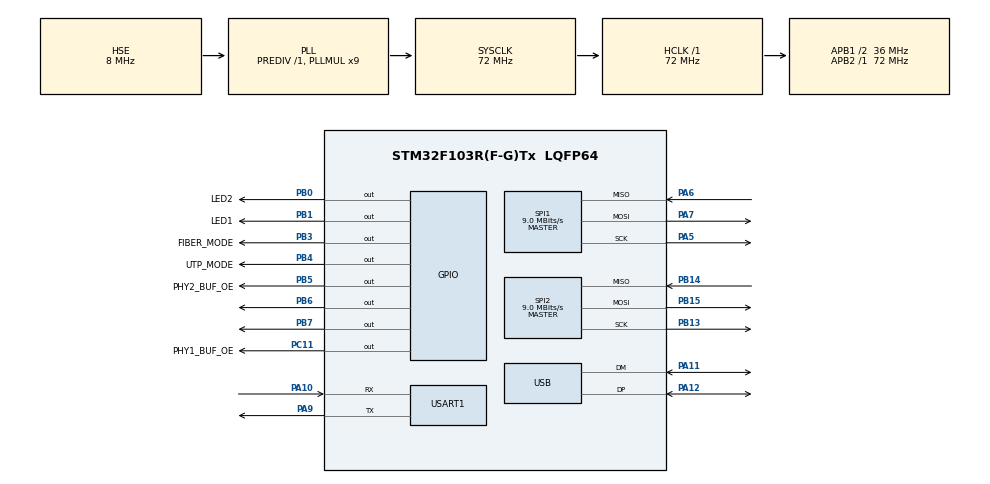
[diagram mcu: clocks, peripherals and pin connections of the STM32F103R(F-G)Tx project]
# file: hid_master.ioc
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Mcu.Family=STM32F1
PA6.Mode=Full_Duplex_Master
USB_DEVICE.CLASS_NAME_FS=CUSTOM_HID
NVIC.DMA1_Channel5_IRQn=true\:0\:0\:false\:false\:true\:false\:true
SPI1.VirtualType=VM_MASTER
Dma.USART1_TX.1.MemInc=DMA_MINC_ENABLE
SPI2.VirtualType=VM_MASTER
VP_USB_DEVICE_VS_USB_DEVICE_CUSTOM_HID_FS.Mode=CUSTOM_HID_FS
PA11.Mode=Device
PB0.GPIO_Label=LED2
PB13.Signal=SPI2_SCK
PB15.Signal=SPI2_MOSI
RCC.SYSCLKSource=RCC_SYSCLKSOURCE_PLLCLK
ProjectManager.StackSize=0x1200
PD1-OSC_OUT.Signal=RCC_OSC_OUT
PA12.Signal=USB_DP
USB_DEVICE.PID_CUSTOMHID_FS=0x00de
PB0.PinState=GPIO_PIN_SET
PB3.PinState=GPIO_PIN_SET
SPI1.Direction=SPI_DIRECTION_2LINES
RCC.HCLKFreq_Value=72000000
RCC.APB2TimFreq_Value=72000000
PB6.Signal=GPIO_Output
SPI1.CalculateBaudRate=9.0 MBits/s
RCC.AHBFreq_Value=72000000
SPI2.BaudRatePrescaler=SPI_BAUDRATEPRESCALER_4
Dma.USART1_RX.0.Priority=DMA_PRIORITY_LOW
RCC.PLLMUL=RCC_PLL_MUL9
PC14-OSC32_IN.Mode=LSE-External-Oscillator
PA14.Mode=Serial_Wire
PB14.Mode=Full_Duplex_Master
PB1.GPIO_Label=LED1
PC11.GPIO_Label=PHY1_BUF_OE
SPI2.CalculateBaudRate=9.0 MBits/s
PB7.Signal=GPIO_Output
SPI1.FirstBit=SPI_FIRSTBIT_MSB
Dma.USART1_RX.0.MemInc=DMA_MINC_ENABLE
VP_TIM1_VS_ClockSourceINT.Mode=Internal
Dma.USART1_TX.1.PeriphDataAlignment=DMA_PDATAALIGN_BYTE
PB1.PinState=GPIO_PIN_SET
Mcu.Package=LQFP64
PB1.Signal=GPIO_Output
PA6.Signal=SPI1_MISO
SPI2.Mode=SPI_MODE_MASTER
PA10.Signal=USART1_RX
PB5.GPIO_Label=PHY2_BUF_OE
Dma.Request1=USART1_TX
RCC.APB1TimFreq_Value=72000000
Dma.USART1_RX.0.Mode=DMA_CIRCULAR
Dma.USART1_TX.1.Priority=DMA_PRIORITY_LOW
SPI2.Direction=SPI_DIRECTION_2LINES
USB_DEVICE.USBD_CUSTOMHID_OUTREPORT_BUF_SIZE=64
PB13.Mode=Full_Duplex_Master
NVIC.DMA1_Channel4_IRQn=true\:0\:0\:false\:false\:true\:false\:true
Dma.Request0=USART1_RX
SPI1.BaudRatePrescaler=SPI_BAUDRATEPRESCALER_8
PB4.PinState=GPIO_PIN_SET
Dma.USART1_RX.0.Instance=DMA1_Channel5
PB4.Signal=GPIO_Output
PA5.Mode=Full_Duplex_Master
Dma.USART1_TX.1.Direction=DMA_MEMORY_TO_PERIPH
PB3.GPIO_Label=FIBER_MODE
PC15-OSC32_OUT.Mode=LSE-External-Oscillator
Dma.USART1_TX.1.Instance=DMA1_Channel4
USB_DEVICE.CUSTOM_HID_FS_BINTERVAL=0x1
PA7.Mode=Full_Duplex_Master
PD1-OSC_OUT.Mode=HSE-External-Oscillator
Dma.USART1_RX.0.PeriphDataAlignment=DMA_PDATAALIGN_BYTE
PA10.Mode=Asynchronous
USB_DEVICE.USBD_CUSTOM_HID_REPORT_DESC_SIZE=34
USB_DEVICE.VirtualModeFS=Custom_Hid_FS
PC11.Signal=GPIO_Output
RCC.USBPrescaler=RCC_USBCLKSOURCE_PLL_DIV1_5
PD0-OSC_IN.Signal=RCC_OSC_IN
RCC.APB1CLKDivider=RCC_HCLK_DIV2
PC14-OSC32_IN.Signal=RCC_OSC32_IN
PA13.Signal=SYS_JTMS-SWDIO
TIM1.AutoReloadPreload=TIM_AUTORELOAD_PRELOAD_ENABLE
PA9.Mode=Asynchronous
USB_DEVICE.VID=0x0483
ProjectManager.TargetToolchain=Makefile
Dma.USART1_RX.0.Direction=DMA_PERIPH_TO_MEMORY
PA9.Signal=USART1_TX
RCC.USBFreq_Value=48000000
PC15-OSC32_OUT.Signal=RCC_OSC32_OUT
Dma.USART1_RX.0.PeriphInc=DMA_PINC_DISABLE
PD0-OSC_IN.Mode=HSE-External-Oscillator
PB14.Signal=SPI2_MISO
PA5.Signal=SPI1_SCK
Dma.USART1_TX.1.MemDataAlignment=DMA_MDATAALIGN_BYTE
board=custom
PB15.Mode=Full_Duplex_Master
RCC.APB2Freq_Value=72000000
PB4.GPIO_Label=UTP_MODE
SPI1.Mode=SPI_MODE_MASTER
NVIC.USB_LP_CAN1_RX0_IRQn=true\:0\:0\:false\:false\:true\:false\:true
Dma.USART1_RX.0.MemDataAlignment=DMA_MDATAALIGN_BYTE
PA13.Mode=Serial_Wire
Mcu.Name=STM32F103R(F-G)Tx
PB3.Signal=GPIO_Output
RCC.SYSCLKFreq_VALUE=72000000
PB5.Signal=GPIO_Output
PA12.Mode=Device
Dma.USART1_TX.1.Mode=DMA_NORMAL
SPI2.FirstBit=SPI_FIRSTBIT_MSB
USART1.VirtualMode=VM_ASYNC
PA11.Signal=USB_DM
PA14.Signal=SYS_JTCK-SWCLK
ProjectManager.HeapSize=0x800
Dma.USART1_TX.1.PeriphInc=DMA_PINC_DISABLE
NVIC.PriorityGroup=NVIC_PRIORITYGROUP_4
RCC.APB1Freq_Value=36000000
PB0.Signal=GPIO_Output
USB_DEVICE.VirtualMode=CustomHid
PA7.Signal=SPI1_MOSI

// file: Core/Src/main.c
/* USER CODE BEGIN Header */
/**
 ******************************************************************************
 * @file           : main.c
 * @brief          : Main program body
 ******************************************************************************
 * @attention
 *
 * <h2><center>&copy; Copyright (c) 2020 STMicroelectronics.
 * All rights reserved.</center></h2>
 *
 * This software component is licensed by ST under Ultimate Liberty license
 * SLA0044, the "License"; You may not use this file except in compliance with
 * the License. You may obtain a copy of the License at:
 *                             www.st.com/SLA0044
 *
 ******************************************************************************
 */
/* USER CODE END Header */
#include "main.h"
#include "dma.h"
#include "spi.h"
#include "tim.h"
#include "usart.h"
#include "usb_device.h"
#include "gpio.h"

void SystemClock_Config(void);

int main(void)
{

        /* MCU Configuration--------------------------------------------------------*/

        /* Reset of all peripherals, Initializes the Flash interface and the Systick. */
        HAL_Init();

        /* Configure the system clock */
        SystemClock_Config();

        /* Initialize all configured peripherals */
        MX_GPIO_Init();
        MX_DMA_Init();
        MX_TIM1_Init();
        MX_USART1_UART_Init();
        MX_USB_DEVICE_Init();
        MX_SPI1_Init();
        MX_SPI2_Init();
        /* USER CODE BEGIN 2 */
        i2c_gpio_init();
	hid_init();
        /* USER CODE END 2 */

        /* Infinite loop */
        while (1)
        {

        }
}

void SystemClock_Config(void)
{
        RCC_OscInitTypeDef RCC_OscInitStruct = {0};
        RCC_ClkInitTypeDef RCC_ClkInitStruct = {0};
        RCC_PeriphCLKInitTypeDef PeriphClkInit = {0};

        /** Initializes the RCC Oscillators according to the specified parameters
         * in the RCC_OscInitTypeDef structure.
         */
        RCC_OscInitStruct.OscillatorType = RCC_OSCILLATORTYPE_HSE;
        RCC_OscInitStruct.HSEState = RCC_HSE_ON;
        RCC_OscInitStruct.HSEPredivValue = RCC_HSE_PREDIV_DIV1;
        RCC_OscInitStruct.HSIState = RCC_HSI_ON;
        RCC_OscInitStruct.PLL.PLLState = RCC_PLL_ON;
        RCC_OscInitStruct.PLL.PLLSource = RCC_PLLSOURCE_HSE;
        RCC_OscInitStruct.PLL.PLLMUL = RCC_PLL_MUL9;
        if (HAL_RCC_OscConfig(&RCC_OscInitStruct) != HAL_OK)
        {
                Error_Handler();
        }
        /** Initializes the CPU, AHB and APB buses clocks
        */
        RCC_ClkInitStruct.ClockType = RCC_CLOCKTYPE_HCLK|RCC_CLOCKTYPE_SYSCLK
                |RCC_CLOCKTYPE_PCLK1|RCC_CLOCKTYPE_PCLK2;
        RCC_ClkInitStruct.SYSCLKSource = RCC_SYSCLKSOURCE_PLLCLK;
        RCC_ClkInitStruct.AHBCLKDivider = RCC_SYSCLK_DIV1;
        RCC_ClkInitStruct.APB1CLKDivider = RCC_HCLK_DIV2;
        RCC_ClkInitStruct.APB2CLKDivider = RCC_HCLK_DIV1;

        if (HAL_RCC_ClockConfig(&RCC_ClkInitStruct, FLASH_LATENCY_2) != HAL_OK)
        {
                Error_Handler();
        }
        PeriphClkInit.PeriphClockSelection = RCC_PERIPHCLK_USB;
        PeriphClkInit.UsbClockSelection = RCC_USBCLKSOURCE_PLL_DIV1_5;
        if (HAL_RCCEx_PeriphCLKConfig(&PeriphClkInit) != HAL_OK)
        {
                Error_Handler();
        }
}

void Error_Handler(void)
{
}

/************************ (C) COPYRIGHT STMicroelectronics *****END OF FILE****/
